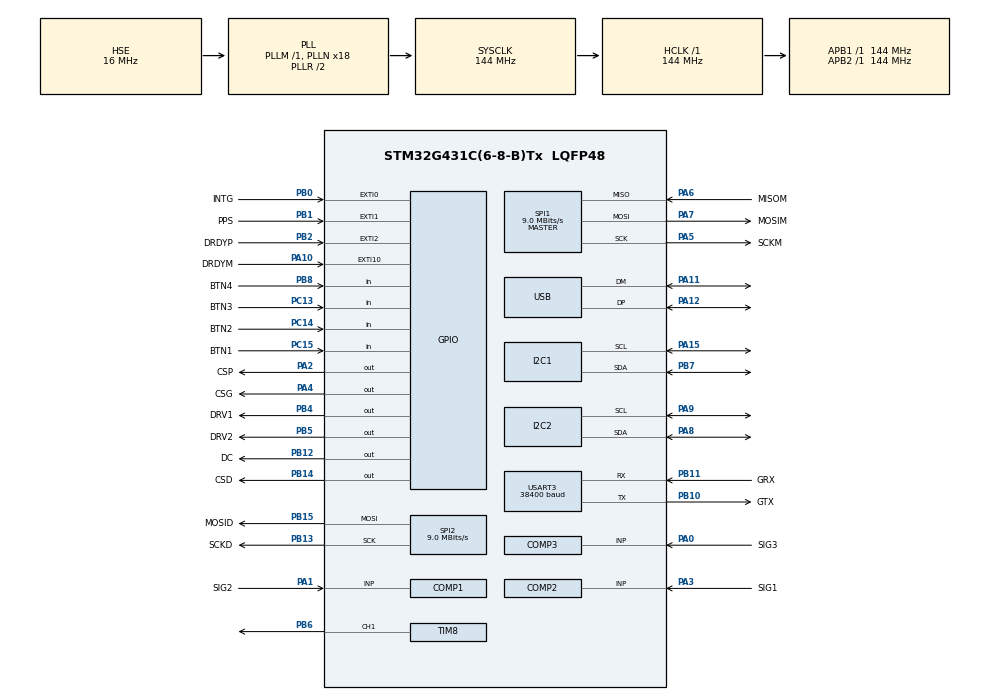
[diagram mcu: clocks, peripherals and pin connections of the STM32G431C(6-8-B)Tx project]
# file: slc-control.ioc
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COMP1.Hysteresis=COMP_HYSTERESIS_HIGH
COMP1.TriggerMode=COMP_TRIGGERMODE_IT_RISING
COMP2.Hysteresis=COMP_HYSTERESIS_HIGH
COMP2.TriggerMode=COMP_TRIGGERMODE_IT_RISING
COMP3.Hysteresis=COMP_HYSTERESIS_HIGH
COMP3.TriggerMode=COMP_TRIGGERMODE_IT_RISING
DAC1.DAC_Channel-DAC_OUT2_Int=DAC_CHANNEL_2
Dma.Request0=USART3_RX
Dma.Request1=USART3_TX
Dma.USART3_RX.0.Direction=DMA_PERIPH_TO_MEMORY
Dma.USART3_RX.0.EventEnable=DISABLE
Dma.USART3_RX.0.Instance=DMA1_Channel1
Dma.USART3_RX.0.MemDataAlignment=DMA_MDATAALIGN_BYTE
Dma.USART3_RX.0.MemInc=DMA_MINC_ENABLE
Dma.USART3_RX.0.Mode=DMA_NORMAL
Dma.USART3_RX.0.PeriphDataAlignment=DMA_PDATAALIGN_BYTE
Dma.USART3_RX.0.PeriphInc=DMA_PINC_DISABLE
Dma.USART3_RX.0.Polarity=HAL_DMAMUX_REQ_GEN_RISING
Dma.USART3_RX.0.Priority=DMA_PRIORITY_HIGH
Dma.USART3_RX.0.RequestNumber=1
Dma.USART3_RX.0.SignalID=NONE
Dma.USART3_RX.0.SyncEnable=DISABLE
Dma.USART3_RX.0.SyncPolarity=HAL_DMAMUX_SYNC_NO_EVENT
Dma.USART3_RX.0.SyncRequestNumber=1
Dma.USART3_RX.0.SyncSignalID=NONE
Dma.USART3_TX.1.Direction=DMA_MEMORY_TO_PERIPH
Dma.USART3_TX.1.EventEnable=DISABLE
Dma.USART3_TX.1.Instance=DMA2_Channel1
Dma.USART3_TX.1.MemDataAlignment=DMA_MDATAALIGN_BYTE
Dma.USART3_TX.1.MemInc=DMA_MINC_ENABLE
Dma.USART3_TX.1.Mode=DMA_NORMAL
Dma.USART3_TX.1.PeriphDataAlignment=DMA_PDATAALIGN_BYTE
Dma.USART3_TX.1.PeriphInc=DMA_PINC_DISABLE
Dma.USART3_TX.1.Polarity=HAL_DMAMUX_REQ_GEN_RISING
Dma.USART3_TX.1.Priority=DMA_PRIORITY_LOW
Dma.USART3_TX.1.RequestNumber=1
Dma.USART3_TX.1.SignalID=NONE
Dma.USART3_TX.1.SyncEnable=DISABLE
Dma.USART3_TX.1.SyncPolarity=HAL_DMAMUX_SYNC_NO_EVENT
Dma.USART3_TX.1.SyncRequestNumber=1
Dma.USART3_TX.1.SyncSignalID=NONE
I2C1.I2C_Fall_Time=10
I2C1.I2C_Rise_Time=10
I2C1.Timing=0xA030354A
I2C2.I2C_Fall_Time=10
I2C2.I2C_Rise_Time=10
I2C2.Timing=0xA030354A
Mcu.Family=STM32G4
Mcu.Name=STM32G431C(6-8-B)Tx
Mcu.Package=LQFP48
NVIC.COMP1_2_3_IRQn=true\:3\:0\:true\:false\:true\:false\:true\:true
NVIC.DMA1_Channel1_IRQn=true\:0\:0\:true\:false\:true\:false\:true\:true
NVIC.PriorityGroup=NVIC_PRIORITYGROUP_4
NVIC.TIM1_UP_TIM16_IRQn=true\:2\:0\:true\:false\:true\:true\:true\:true
NVIC.TIM2_IRQn=true\:4\:0\:true\:false\:true\:true\:true\:true
NVIC.TIM3_IRQn=true\:7\:0\:true\:false\:true\:true\:true\:true
NVIC.USART3_IRQn=true\:1\:0\:true\:false\:true\:true\:true\:true
NVIC.USB_LP_IRQn=true\:0\:0\:true\:false\:true\:false\:true\:true
PA0.GPIO_Label=SIG3
PA0.Mode=INP
PA0.Signal=COMP3_INP
PA1.GPIO_Label=SIG2
PA1.Mode=INP
PA1.Signal=COMP1_INP
PA10.GPIO_Label=DRDYM
PA10.Signal=GPXTI10
PA11.Mode=Device
PA11.Signal=USB_DM
PA12.Mode=Device
PA12.Signal=USB_DP
PA13.Mode=Trace_Asynchronous_SW
PA13.Signal=SYS_JTMS-SWDIO
PA14.Mode=Trace_Asynchronous_SW
PA14.Signal=SYS_JTCK-SWCLK
PA15.Mode=I2C
PA15.Signal=I2C1_SCL
PA2.GPIO_Label=CSP
PA2.GPIO_Speed=GPIO_SPEED_FREQ_HIGH
PA2.PinState=GPIO_PIN_SET
PA2.Signal=GPIO_Output
PA3.GPIO_Label=SIG1
PA3.Mode=INP
PA3.Signal=COMP2_INP
PA4.GPIO_Label=CSG
PA4.GPIO_Speed=GPIO_SPEED_FREQ_HIGH
PA4.PinState=GPIO_PIN_SET
PA4.Signal=GPIO_Output
PA5.GPIO_Label=SCKM
PA5.Mode=Full_Duplex_Master
PA5.Signal=SPI1_SCK
PA6.GPIO_Label=MISOM
PA6.Mode=Full_Duplex_Master
PA6.Signal=SPI1_MISO
PA7.GPIO_Label=MOSIM
PA7.Mode=Full_Duplex_Master
PA7.Signal=SPI1_MOSI
PA8.Mode=I2C
PA8.Signal=I2C2_SDA
PA9.Mode=I2C
PA9.Signal=I2C2_SCL
PB0.GPIO_Label=INTG
PB0.Signal=GPXTI0
PB1.GPIO_Label=PPS
PB1.Signal=GPXTI1
PB10.GPIO_Label=GTX
PB10.Mode=Asynchronous
PB10.Signal=USART3_TX
PB11.GPIO_Label=GRX
PB11.Mode=Asynchronous
PB11.Signal=USART3_RX
PB12.GPIO_Label=DC
PB12.GPIO_Speed=GPIO_SPEED_FREQ_HIGH
PB12.Signal=GPIO_Output
PB13.GPIO_Label=SCKD
PB13.Mode=TX_Only_Simplex_Unidirect_Master
PB13.Signal=SPI2_SCK
PB14.GPIO_Label=CSD
PB14.GPIO_Speed=GPIO_SPEED_FREQ_HIGH
PB14.PinState=GPIO_PIN_SET
PB14.Signal=GPIO_Output
PB15.GPIO_Label=MOSID
PB15.Mode=TX_Only_Simplex_Unidirect_Master
PB15.Signal=SPI2_MOSI
PB2.GPIO_Label=DRDYP
PB2.Signal=GPXTI2
PB3.Mode=Trace_Asynchronous_SW
PB3.Signal=SYS_JTDO-SWO
PB4.GPIO_Label=DRV1
PB4.GPIO_Speed=GPIO_SPEED_FREQ_MEDIUM
PB4.Signal=GPIO_Output
PB5.GPIO_Label=DRV2
PB5.GPIO_Speed=GPIO_SPEED_FREQ_MEDIUM
PB5.Signal=GPIO_Output
PB6.Signal=S_TIM8_CH1
PB7.Mode=I2C
PB7.Signal=I2C1_SDA
PB8-BOOT0.GPIO_Label=BTN4
PB8-BOOT0.GPIO_PuPd=GPIO_PULLUP
PB8-BOOT0.Signal=GPIO_Input
PC13.GPIO_Label=BTN3
PC13.GPIO_PuPd=GPIO_PULLUP
PC13.Signal=GPIO_Input
PC14-OSC32_IN.GPIO_Label=BTN2
PC14-OSC32_IN.GPIO_PuPd=GPIO_PULLUP
PC14-OSC32_IN.Signal=GPIO_Input
PC15-OSC32_OUT.GPIO_Label=BTN1
PC15-OSC32_OUT.GPIO_PuPd=GPIO_PULLUP
PC15-OSC32_OUT.Signal=GPIO_Input
PF0-OSC_IN.Mode=HSE-External-Oscillator
PF0-OSC_IN.Signal=RCC_OSC_IN
PF1-OSC_OUT.Mode=HSE-External-Oscillator
PF1-OSC_OUT.Signal=RCC_OSC_OUT
ProjectManager.HeapSize=0x200
ProjectManager.StackSize=0x400
ProjectManager.TargetToolchain=CMake
RCC.ADC12Freq_Value=144000000
RCC.AHBFreq_Value=144000000
RCC.APB1Freq_Value=144000000
RCC.APB1TimFreq_Value=144000000
RCC.APB2Freq_Value=144000000
RCC.APB2TimFreq_Value=144000000
RCC.CortexFreq_Value=144000000
RCC.EXTERNAL_CLOCK_VALUE=12288000
RCC.HCLKFreq_Value=144000000
RCC.HSE_Timout=1000
RCC.HSE_VALUE=16000000
RCC.HSI48_VALUE=48000000
RCC.HSI_VALUE=16000000
RCC.I2C1CLockSelection=RCC_I2C1CLKSOURCE_SYSCLK
RCC.I2C2CLockSelection=RCC_I2C2CLKSOURCE_SYSCLK
RCC.LSE_VALUE=32768
RCC.PLLN=18
RCC.PLLQ=RCC_PLLQ_DIV6
RCC.PLLSourceVirtual=RCC_PLLSOURCE_HSE
RCC.PREFETCH_ENABLE=1
RCC.SYSCLKFreq_VALUE=144000000
RCC.SYSCLKSource=RCC_SYSCLKSOURCE_PLLCLK
RCC.USART3CLockSelection=RCC_USART3CLKSOURCE_SYSCLK
RCC.USBFreq_Value=48000000
RCC.VCOOutputFreq_Value=288000000
SH.S_TIM8_CH1.0=TIM8_CH1,PWM Generation1 CH1
SPI1.BaudRatePrescaler=SPI_BAUDRATEPRESCALER_16
SPI1.CalculateBaudRate=9.0 MBits/s
SPI1.DataSize=SPI_DATASIZE_8BIT
SPI1.Direction=SPI_DIRECTION_2LINES
SPI1.Mode=SPI_MODE_MASTER
SPI1.VirtualType=VM_MASTER
SPI2.BaudRatePrescaler=SPI_BAUDRATEPRESCALER_16
SPI2.CalculateBaudRate=9.0 MBits/s
SPI2.DataSize=SPI_DATASIZE_8BIT
SPI2.Direction=SPI_DIRECTION_2LINES
SPI2.Mode=SPI_MODE_MASTER
SPI2.VirtualType=VM_MASTER
TIM1.PeriodNoDither=100-1
TIM1.Prescaler=144-1
TIM2.PeriodNoDither=100000-1
TIM2.Prescaler=144-1
TIM3.PeriodNoDither=20000-1
TIM3.Prescaler=144-1
TIM8.Channel-PWM\ Generation1\ CH1=TIM_CHANNEL_1
TIM8.PeriodNoDither=1000
TIM8.Prescaler=65535
TIM8.PulseNoDither_1=100
USART3.BaudRate=38400
USART3.VirtualMode-Asynchronous=VM_ASYNC
USB_DEVICE.CLASS_NAME_FS=CDC
USB_DEVICE.PRODUCT_STRING_CDC_FS=slc-control
USB_DEVICE.VirtualMode=Cdc
USB_DEVICE.VirtualModeFS=Cdc_FS
VP_COMP1_VS_DAC1OUT1.Mode=INM_DAC1OUT1
VP_COMP2_VS_DAC1OUT2.Mode=INM_DAC1OUT2
VP_COMP3_VS_DAC3OUT1.Mode=INM_DAC3OUT1
VP_DAC1_VS_DACI1.Mode=DAC_OUT1_Int
VP_DAC1_VS_DACI2.Mode=DAC_OUT2_Int
VP_DAC3_VS_DACI1.Mode=DAC_OUT1_Int
VP_SYS_VS_DBSignals.Mode=DisableDeadBatterySignals
VP_TIM1_VS_ClockSourceINT.Mode=Internal
VP_TIM2_VS_ClockSourceINT.Mode=Internal
VP_TIM3_VS_ClockSourceINT.Mode=Internal
VP_TIM8_VS_ClockSourceINT.Mode=Internal
VP_USB_DEVICE_VS_USB_DEVICE_CDC_FS.Mode=CDC_FS
board=custom

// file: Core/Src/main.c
/* USER CODE BEGIN Header */
/**
  ******************************************************************************
  * @file           : main.c
  * @brief          : Main program body
  ******************************************************************************
  * @attention
  *
  * Copyright (c) 2025 STMicroelectronics.
  * All rights reserved.
  *
  * This software is licensed under terms that can be found in the LICENSE file
  * in the root directory of this software component.
  * If no LICENSE file comes with this software, it is provided AS-IS.
  *
  ******************************************************************************
  */
/* USER CODE END Header */
#include "main.h"
#include "usb_device.h"

/* USER CODE BEGIN Includes */
#include "app.h"
/* USER CODE END Includes */

COMP_HandleTypeDef hcomp1;
COMP_HandleTypeDef hcomp2;
COMP_HandleTypeDef hcomp3;

DAC_HandleTypeDef hdac1;
DAC_HandleTypeDef hdac3;

I2C_HandleTypeDef hi2c1;
I2C_HandleTypeDef hi2c2;

SPI_HandleTypeDef hspi1;
SPI_HandleTypeDef hspi2;

TIM_HandleTypeDef htim1;
TIM_HandleTypeDef htim2;
TIM_HandleTypeDef htim3;
TIM_HandleTypeDef htim8;

UART_HandleTypeDef huart3;
DMA_HandleTypeDef hdma_usart3_rx;
DMA_HandleTypeDef hdma_usart3_tx;

void SystemClock_Config(void);
static void MX_GPIO_Init(void);
static void MX_DMA_Init(void);
static void MX_I2C1_Init(void);
static void MX_I2C2_Init(void);
static void MX_SPI1_Init(void);
static void MX_SPI2_Init(void);
static void MX_USART3_UART_Init(void);
static void MX_COMP1_Init(void);
static void MX_COMP2_Init(void);
static void MX_COMP3_Init(void);
static void MX_DAC1_Init(void);
static void MX_DAC3_Init(void);
static void MX_TIM1_Init(void);
static void MX_TIM2_Init(void);
static void MX_TIM3_Init(void);
static void MX_TIM8_Init(void);

int main(void)
{

  /* MCU Configuration--------------------------------------------------------*/

  /* Reset of all peripherals, Initializes the Flash interface and the Systick. */
  HAL_Init();

  /* Configure the system clock */
  SystemClock_Config();

  /* Initialize all configured peripherals */
  MX_GPIO_Init();
  MX_DMA_Init();
  MX_I2C1_Init();
  MX_I2C2_Init();
  MX_SPI1_Init();
  MX_SPI2_Init();
  MX_USART3_UART_Init();
  MX_USB_Device_Init();
  MX_COMP1_Init();
  MX_COMP2_Init();
  MX_COMP3_Init();
  MX_DAC1_Init();
  MX_DAC3_Init();
  MX_TIM1_Init();
  MX_TIM2_Init();
  MX_TIM3_Init();
  MX_TIM8_Init();

  /* Infinite loop */
  /* USER CODE BEGIN WHILE */
  App_Init();
  while (1)
  {
    App_Update();
    /* USER CODE END WHILE */

  }
}

void SystemClock_Config(void)
{
  RCC_OscInitTypeDef RCC_OscInitStruct = {0};
  RCC_ClkInitTypeDef RCC_ClkInitStruct = {0};

  /** Configure the main internal regulator output voltage
  */
  HAL_PWREx_ControlVoltageScaling(PWR_REGULATOR_VOLTAGE_SCALE1);

  /** Initializes the RCC Oscillators according to the specified parameters
  * in the RCC_OscInitTypeDef structure.
  */
  RCC_OscInitStruct.OscillatorType = RCC_OSCILLATORTYPE_HSE;
  RCC_OscInitStruct.HSEState = RCC_HSE_ON;
  RCC_OscInitStruct.PLL.PLLState = RCC_PLL_ON;
  RCC_OscInitStruct.PLL.PLLSource = RCC_PLLSOURCE_HSE;
  RCC_OscInitStruct.PLL.PLLM = RCC_PLLM_DIV1;
  RCC_OscInitStruct.PLL.PLLN = 18;
  RCC_OscInitStruct.PLL.PLLP = RCC_PLLP_DIV2;
  RCC_OscInitStruct.PLL.PLLQ = RCC_PLLQ_DIV6;
  RCC_OscInitStruct.PLL.PLLR = RCC_PLLR_DIV2;
  if (HAL_RCC_OscConfig(&RCC_OscInitStruct) != HAL_OK)
  {
    Error_Handler();
  }

  /** Initializes the CPU, AHB and APB buses clocks
  */
  RCC_ClkInitStruct.ClockType = RCC_CLOCKTYPE_HCLK|RCC_CLOCKTYPE_SYSCLK
                              |RCC_CLOCKTYPE_PCLK1|RCC_CLOCKTYPE_PCLK2;
  RCC_ClkInitStruct.SYSCLKSource = RCC_SYSCLKSOURCE_PLLCLK;
  RCC_ClkInitStruct.AHBCLKDivider = RCC_SYSCLK_DIV1;
  RCC_ClkInitStruct.APB1CLKDivider = RCC_HCLK_DIV1;
  RCC_ClkInitStruct.APB2CLKDivider = RCC_HCLK_DIV1;

  if (HAL_RCC_ClockConfig(&RCC_ClkInitStruct, FLASH_LATENCY_4) != HAL_OK)
  {
    Error_Handler();
  }
}

static void MX_COMP1_Init(void)
{

  hcomp1.Instance = COMP1;
  hcomp1.Init.InputPlus = COMP_INPUT_PLUS_IO1;
  hcomp1.Init.InputMinus = COMP_INPUT_MINUS_DAC1_CH1;
  hcomp1.Init.OutputPol = COMP_OUTPUTPOL_NONINVERTED;
  hcomp1.Init.Hysteresis = COMP_HYSTERESIS_HIGH;
  hcomp1.Init.BlankingSrce = COMP_BLANKINGSRC_NONE;
  hcomp1.Init.TriggerMode = COMP_TRIGGERMODE_IT_RISING;
  if (HAL_COMP_Init(&hcomp1) != HAL_OK)
  {
    Error_Handler();
  }

}

static void MX_COMP2_Init(void)
{

  hcomp2.Instance = COMP2;
  hcomp2.Init.InputPlus = COMP_INPUT_PLUS_IO2;
  hcomp2.Init.InputMinus = COMP_INPUT_MINUS_DAC1_CH2;
  hcomp2.Init.OutputPol = COMP_OUTPUTPOL_NONINVERTED;
  hcomp2.Init.Hysteresis = COMP_HYSTERESIS_HIGH;
  hcomp2.Init.BlankingSrce = COMP_BLANKINGSRC_NONE;
  hcomp2.Init.TriggerMode = COMP_TRIGGERMODE_IT_RISING;
  if (HAL_COMP_Init(&hcomp2) != HAL_OK)
  {
    Error_Handler();
  }

}

static void MX_COMP3_Init(void)
{

  hcomp3.Instance = COMP3;
  hcomp3.Init.InputPlus = COMP_INPUT_PLUS_IO1;
  hcomp3.Init.InputMinus = COMP_INPUT_MINUS_DAC3_CH1;
  hcomp3.Init.OutputPol = COMP_OUTPUTPOL_NONINVERTED;
  hcomp3.Init.Hysteresis = COMP_HYSTERESIS_HIGH;
  hcomp3.Init.BlankingSrce = COMP_BLANKINGSRC_NONE;
  hcomp3.Init.TriggerMode = COMP_TRIGGERMODE_IT_RISING;
  if (HAL_COMP_Init(&hcomp3) != HAL_OK)
  {
    Error_Handler();
  }

}

static void MX_DAC1_Init(void)
{

  DAC_ChannelConfTypeDef sConfig = {0};

  /** DAC Initialization
  */
  hdac1.Instance = DAC1;
  if (HAL_DAC_Init(&hdac1) != HAL_OK)
  {
    Error_Handler();
  }

  /** DAC channel OUT1 config
  */
  sConfig.DAC_HighFrequency = DAC_HIGH_FREQUENCY_INTERFACE_MODE_AUTOMATIC;
  sConfig.DAC_DMADoubleDataMode = DISABLE;
  sConfig.DAC_SignedFormat = DISABLE;
  sConfig.DAC_SampleAndHold = DAC_SAMPLEANDHOLD_DISABLE;
  sConfig.DAC_Trigger = DAC_TRIGGER_NONE;
  sConfig.DAC_Trigger2 = DAC_TRIGGER_NONE;
  sConfig.DAC_OutputBuffer = DAC_OUTPUTBUFFER_DISABLE;
  sConfig.DAC_ConnectOnChipPeripheral = DAC_CHIPCONNECT_INTERNAL;
  sConfig.DAC_UserTrimming = DAC_TRIMMING_FACTORY;
  if (HAL_DAC_ConfigChannel(&hdac1, &sConfig, DAC_CHANNEL_1) != HAL_OK)
  {
    Error_Handler();
  }

  /** DAC channel OUT2 config
  */
  if (HAL_DAC_ConfigChannel(&hdac1, &sConfig, DAC_CHANNEL_2) != HAL_OK)
  {
    Error_Handler();
  }

}

static void MX_DAC3_Init(void)
{

  DAC_ChannelConfTypeDef sConfig = {0};

  /** DAC Initialization
  */
  hdac3.Instance = DAC3;
  if (HAL_DAC_Init(&hdac3) != HAL_OK)
  {
    Error_Handler();
  }

  /** DAC channel OUT1 config
  */
  sConfig.DAC_HighFrequency = DAC_HIGH_FREQUENCY_INTERFACE_MODE_AUTOMATIC;
  sConfig.DAC_DMADoubleDataMode = DISABLE;
  sConfig.DAC_SignedFormat = DISABLE;
  sConfig.DAC_SampleAndHold = DAC_SAMPLEANDHOLD_DISABLE;
  sConfig.DAC_Trigger = DAC_TRIGGER_NONE;
  sConfig.DAC_Trigger2 = DAC_TRIGGER_NONE;
  sConfig.DAC_OutputBuffer = DAC_OUTPUTBUFFER_DISABLE;
  sConfig.DAC_ConnectOnChipPeripheral = DAC_CHIPCONNECT_INTERNAL;
  sConfig.DAC_UserTrimming = DAC_TRIMMING_FACTORY;
  if (HAL_DAC_ConfigChannel(&hdac3, &sConfig, DAC_CHANNEL_1) != HAL_OK)
  {
    Error_Handler();
  }

}

static void MX_I2C1_Init(void)
{

  hi2c1.Instance = I2C1;
  hi2c1.Init.Timing = 0xA030354A;
  hi2c1.Init.OwnAddress1 = 0;
  hi2c1.Init.AddressingMode = I2C_ADDRESSINGMODE_7BIT;
  hi2c1.Init.DualAddressMode = I2C_DUALADDRESS_DISABLE;
  hi2c1.Init.OwnAddress2 = 0;
  hi2c1.Init.OwnAddress2Masks = I2C_OA2_NOMASK;
  hi2c1.Init.GeneralCallMode = I2C_GENERALCALL_DISABLE;
  hi2c1.Init.NoStretchMode = I2C_NOSTRETCH_DISABLE;
  if (HAL_I2C_Init(&hi2c1) != HAL_OK)
  {
    Error_Handler();
  }

  /** Configure Analogue filter
  */
  if (HAL_I2CEx_ConfigAnalogFilter(&hi2c1, I2C_ANALOGFILTER_ENABLE) != HAL_OK)
  {
    Error_Handler();
  }

  /** Configure Digital filter
  */
  if (HAL_I2CEx_ConfigDigitalFilter(&hi2c1, 0) != HAL_OK)
  {
    Error_Handler();
  }

}

static void MX_I2C2_Init(void)
{

  hi2c2.Instance = I2C2;
  hi2c2.Init.Timing = 0xA030354A;
  hi2c2.Init.OwnAddress1 = 0;
  hi2c2.Init.AddressingMode = I2C_ADDRESSINGMODE_7BIT;
  hi2c2.Init.DualAddressMode = I2C_DUALADDRESS_DISABLE;
  hi2c2.Init.OwnAddress2 = 0;
  hi2c2.Init.OwnAddress2Masks = I2C_OA2_NOMASK;
  hi2c2.Init.GeneralCallMode = I2C_GENERALCALL_DISABLE;
  hi2c2.Init.NoStretchMode = I2C_NOSTRETCH_DISABLE;
  if (HAL_I2C_Init(&hi2c2) != HAL_OK)
  {
    Error_Handler();
  }

  /** Configure Analogue filter
  */
  if (HAL_I2CEx_ConfigAnalogFilter(&hi2c2, I2C_ANALOGFILTER_ENABLE) != HAL_OK)
  {
    Error_Handler();
  }

  /** Configure Digital filter
  */
  if (HAL_I2CEx_ConfigDigitalFilter(&hi2c2, 0) != HAL_OK)
  {
    Error_Handler();
  }

}

static void MX_SPI1_Init(void)
{

  /* SPI1 parameter configuration*/
  hspi1.Instance = SPI1;
  hspi1.Init.Mode = SPI_MODE_MASTER;
  hspi1.Init.Direction = SPI_DIRECTION_2LINES;
  hspi1.Init.DataSize = SPI_DATASIZE_8BIT;
  hspi1.Init.CLKPolarity = SPI_POLARITY_LOW;
  hspi1.Init.CLKPhase = SPI_PHASE_1EDGE;
  hspi1.Init.NSS = SPI_NSS_SOFT;
  hspi1.Init.BaudRatePrescaler = SPI_BAUDRATEPRESCALER_16;
  hspi1.Init.FirstBit = SPI_FIRSTBIT_MSB;
  hspi1.Init.TIMode = SPI_TIMODE_DISABLE;
  hspi1.Init.CRCCalculation = SPI_CRCCALCULATION_DISABLE;
  hspi1.Init.CRCPolynomial = 7;
  hspi1.Init.CRCLength = SPI_CRC_LENGTH_DATASIZE;
  hspi1.Init.NSSPMode = SPI_NSS_PULSE_ENABLE;
  if (HAL_SPI_Init(&hspi1) != HAL_OK)
  {
    Error_Handler();
  }

}

static void MX_SPI2_Init(void)
{

  /* SPI2 parameter configuration*/
  hspi2.Instance = SPI2;
  hspi2.Init.Mode = SPI_MODE_MASTER;
  hspi2.Init.Direction = SPI_DIRECTION_2LINES;
  hspi2.Init.DataSize = SPI_DATASIZE_8BIT;
  hspi2.Init.CLKPolarity = SPI_POLARITY_LOW;
  hspi2.Init.CLKPhase = SPI_PHASE_1EDGE;
  hspi2.Init.NSS = SPI_NSS_SOFT;
  hspi2.Init.BaudRatePrescaler = SPI_BAUDRATEPRESCALER_16;
  hspi2.Init.FirstBit = SPI_FIRSTBIT_MSB;
  hspi2.Init.TIMode = SPI_TIMODE_DISABLE;
  hspi2.Init.CRCCalculation = SPI_CRCCALCULATION_DISABLE;
  hspi2.Init.CRCPolynomial = 7;
  hspi2.Init.CRCLength = SPI_CRC_LENGTH_DATASIZE;
  hspi2.Init.NSSPMode = SPI_NSS_PULSE_ENABLE;
  if (HAL_SPI_Init(&hspi2) != HAL_OK)
  {
    Error_Handler();
  }

}

static void MX_TIM1_Init(void)
{

  TIM_ClockConfigTypeDef sClockSourceConfig = {0};
  TIM_MasterConfigTypeDef sMasterConfig = {0};

  htim1.Instance = TIM1;
  htim1.Init.Prescaler = 144-1;
  htim1.Init.CounterMode = TIM_COUNTERMODE_UP;
  htim1.Init.Period = 99;
  htim1.Init.ClockDivision = TIM_CLOCKDIVISION_DIV1;
  htim1.Init.RepetitionCounter = 0;
  htim1.Init.AutoReloadPreload = TIM_AUTORELOAD_PRELOAD_DISABLE;
  if (HAL_TIM_Base_Init(&htim1) != HAL_OK)
  {
    Error_Handler();
  }
  sClockSourceConfig.ClockSource = TIM_CLOCKSOURCE_INTERNAL;
  if (HAL_TIM_ConfigClockSource(&htim1, &sClockSourceConfig) != HAL_OK)
  {
    Error_Handler();
  }
  sMasterConfig.MasterOutputTrigger = TIM_TRGO_RESET;
  sMasterConfig.MasterOutputTrigger2 = TIM_TRGO2_RESET;
  sMasterConfig.MasterSlaveMode = TIM_MASTERSLAVEMODE_DISABLE;
  if (HAL_TIMEx_MasterConfigSynchronization(&htim1, &sMasterConfig) != HAL_OK)
  {
    Error_Handler();
  }

}

static void MX_TIM2_Init(void)
{

  TIM_ClockConfigTypeDef sClockSourceConfig = {0};
  TIM_MasterConfigTypeDef sMasterConfig = {0};

  htim2.Instance = TIM2;
  htim2.Init.Prescaler = 144-1;
  htim2.Init.CounterMode = TIM_COUNTERMODE_UP;
  htim2.Init.Period = 99999;
  htim2.Init.ClockDivision = TIM_CLOCKDIVISION_DIV1;
  htim2.Init.AutoReloadPreload = TIM_AUTORELOAD_PRELOAD_DISABLE;
  if (HAL_TIM_Base_Init(&htim2) != HAL_OK)
  {
    Error_Handler();
  }
  sClockSourceConfig.ClockSource = TIM_CLOCKSOURCE_INTERNAL;
  if (HAL_TIM_ConfigClockSource(&htim2, &sClockSourceConfig) != HAL_OK)
  {
    Error_Handler();
  }
  sMasterConfig.MasterOutputTrigger = TIM_TRGO_RESET;
  sMasterConfig.MasterSlaveMode = TIM_MASTERSLAVEMODE_DISABLE;
  if (HAL_TIMEx_MasterConfigSynchronization(&htim2, &sMasterConfig) != HAL_OK)
  {
    Error_Handler();
  }

}

static void MX_TIM3_Init(void)
{

  TIM_ClockConfigTypeDef sClockSourceConfig = {0};
  TIM_MasterConfigTypeDef sMasterConfig = {0};

  htim3.Instance = TIM3;
  htim3.Init.Prescaler = 144-1;
  htim3.Init.CounterMode = TIM_COUNTERMODE_UP;
  htim3.Init.Period = 19999;
  htim3.Init.ClockDivision = TIM_CLOCKDIVISION_DIV1;
  htim3.Init.AutoReloadPreload = TIM_AUTORELOAD_PRELOAD_DISABLE;
  if (HAL_TIM_Base_Init(&htim3) != HAL_OK)
  {
    Error_Handler();
  }
  sClockSourceConfig.ClockSource = TIM_CLOCKSOURCE_INTERNAL;
  if (HAL_TIM_ConfigClockSource(&htim3, &sClockSourceConfig) != HAL_OK)
  {
    Error_Handler();
  }
  sMasterConfig.MasterOutputTrigger = TIM_TRGO_RESET;
  sMasterConfig.MasterSlaveMode = TIM_MASTERSLAVEMODE_DISABLE;
  if (HAL_TIMEx_MasterConfigSynchronization(&htim3, &sMasterConfig) != HAL_OK)
  {
    Error_Handler();
  }

}

static void MX_TIM8_Init(void)
{

  TIM_ClockConfigTypeDef sClockSourceConfig = {0};
  TIM_MasterConfigTypeDef sMasterConfig = {0};
  TIM_OC_InitTypeDef sConfigOC = {0};
  TIM_BreakDeadTimeConfigTypeDef sBreakDeadTimeConfig = {0};

  htim8.Instance = TIM8;
  htim8.Init.Prescaler = 65535;
  htim8.Init.CounterMode = TIM_COUNTERMODE_UP;
  htim8.Init.Period = 1000;
  htim8.Init.ClockDivision = TIM_CLOCKDIVISION_DIV1;
  htim8.Init.RepetitionCounter = 0;
  htim8.Init.AutoReloadPreload = TIM_AUTORELOAD_PRELOAD_DISABLE;
  if (HAL_TIM_Base_Init(&htim8) != HAL_OK)
  {
    Error_Handler();
  }
  sClockSourceConfig.ClockSource = TIM_CLOCKSOURCE_INTERNAL;
  if (HAL_TIM_ConfigClockSource(&htim8, &sClockSourceConfig) != HAL_OK)
  {
    Error_Handler();
  }
  if (HAL_TIM_PWM_Init(&htim8) != HAL_OK)
  {
    Error_Handler();
  }
  sMasterConfig.MasterOutputTrigger = TIM_TRGO_RESET;
  sMasterConfig.MasterOutputTrigger2 = TIM_TRGO2_RESET;
  sMasterConfig.MasterSlaveMode = TIM_MASTERSLAVEMODE_DISABLE;
  if (HAL_TIMEx_MasterConfigSynchronization(&htim8, &sMasterConfig) != HAL_OK)
  {
    Error_Handler();
  }
  sConfigOC.OCMode = TIM_OCMODE_PWM1;
  sConfigOC.Pulse = 100;
  sConfigOC.OCPolarity = TIM_OCPOLARITY_HIGH;
  sConfigOC.OCNPolarity = TIM_OCNPOLARITY_HIGH;
  sConfigOC.OCFastMode = TIM_OCFAST_DISABLE;
  sConfigOC.OCIdleState = TIM_OCIDLESTATE_RESET;
  sConfigOC.OCNIdleState = TIM_OCNIDLESTATE_RESET;
  if (HAL_TIM_PWM_ConfigChannel(&htim8, &sConfigOC, TIM_CHANNEL_1) != HAL_OK)
  {
    Error_Handler();
  }
  sBreakDeadTimeConfig.OffStateRunMode = TIM_OSSR_DISABLE;
  sBreakDeadTimeConfig.OffStateIDLEMode = TIM_OSSI_DISABLE;
  sBreakDeadTimeConfig.LockLevel = TIM_LOCKLEVEL_OFF;
  sBreakDeadTimeConfig.DeadTime = 0;
  sBreakDeadTimeConfig.BreakState = TIM_BREAK_DISABLE;
  sBreakDeadTimeConfig.BreakPolarity = TIM_BREAKPOLARITY_HIGH;
  sBreakDeadTimeConfig.BreakFilter = 0;
  sBreakDeadTimeConfig.BreakAFMode = TIM_BREAK_AFMODE_INPUT;
  sBreakDeadTimeConfig.Break2State = TIM_BREAK2_DISABLE;
  sBreakDeadTimeConfig.Break2Polarity = TIM_BREAK2POLARITY_HIGH;
  sBreakDeadTimeConfig.Break2Filter = 0;
  sBreakDeadTimeConfig.Break2AFMode = TIM_BREAK_AFMODE_INPUT;
  sBreakDeadTimeConfig.AutomaticOutput = TIM_AUTOMATICOUTPUT_DISABLE;
  if (HAL_TIMEx_ConfigBreakDeadTime(&htim8, &sBreakDeadTimeConfig) != HAL_OK)
  {
    Error_Handler();
  }
  HAL_TIM_MspPostInit(&htim8);

}

static void MX_USART3_UART_Init(void)
{

  huart3.Instance = USART3;
  huart3.Init.BaudRate = 38400;
  huart3.Init.WordLength = UART_WORDLENGTH_8B;
  huart3.Init.StopBits = UART_STOPBITS_1;
  huart3.Init.Parity = UART_PARITY_NONE;
  huart3.Init.Mode = UART_MODE_TX_RX;
  huart3.Init.HwFlowCtl = UART_HWCONTROL_NONE;
  huart3.Init.OverSampling = UART_OVERSAMPLING_16;
  huart3.Init.OneBitSampling = UART_ONE_BIT_SAMPLE_DISABLE;
  huart3.Init.ClockPrescaler = UART_PRESCALER_DIV1;
  huart3.AdvancedInit.AdvFeatureInit = UART_ADVFEATURE_NO_INIT;
  if (HAL_UART_Init(&huart3) != HAL_OK)
  {
    Error_Handler();
  }
  if (HAL_UARTEx_SetTxFifoThreshold(&huart3, UART_TXFIFO_THRESHOLD_1_8) != HAL_OK)
  {
    Error_Handler();
  }
  if (HAL_UARTEx_SetRxFifoThreshold(&huart3, UART_RXFIFO_THRESHOLD_1_8) != HAL_OK)
  {
    Error_Handler();
  }
  if (HAL_UARTEx_DisableFifoMode(&huart3) != HAL_OK)
  {
    Error_Handler();
  }

}

static void MX_DMA_Init(void)
{

  /* DMA controller clock enable */
  __HAL_RCC_DMAMUX1_CLK_ENABLE();
  __HAL_RCC_DMA1_CLK_ENABLE();
  __HAL_RCC_DMA2_CLK_ENABLE();

  /* DMA interrupt init */
  /* DMA1_Channel1_IRQn interrupt configuration */
  HAL_NVIC_SetPriority(DMA1_Channel1_IRQn, 0, 0);
  HAL_NVIC_EnableIRQ(DMA1_Channel1_IRQn);

}

static void MX_GPIO_Init(void)
{
  GPIO_InitTypeDef GPIO_InitStruct = {0};

  /* GPIO Ports Clock Enable */
  __HAL_RCC_GPIOC_CLK_ENABLE();
  __HAL_RCC_GPIOF_CLK_ENABLE();
  __HAL_RCC_GPIOA_CLK_ENABLE();
  __HAL_RCC_GPIOB_CLK_ENABLE();

  /*Configure GPIO pin Output Level */
  HAL_GPIO_WritePin(GPIOA, CSP_Pin|CSG_Pin, GPIO_PIN_SET);

  /*Configure GPIO pin Output Level */
  HAL_GPIO_WritePin(GPIOB, DC_Pin|DRV1_Pin|DRV2_Pin, GPIO_PIN_RESET);

  /*Configure GPIO pin Output Level */
  HAL_GPIO_WritePin(CSD_GPIO_Port, CSD_Pin, GPIO_PIN_SET);

  /*Configure GPIO pins : BTN3_Pin BTN2_Pin BTN1_Pin */
  GPIO_InitStruct.Pin = BTN3_Pin|BTN2_Pin|BTN1_Pin;
  GPIO_InitStruct.Mode = GPIO_MODE_INPUT;
  GPIO_InitStruct.Pull = GPIO_PULLUP;
  HAL_GPIO_Init(GPIOC, &GPIO_InitStruct);

  /*Configure GPIO pins : CSP_Pin CSG_Pin */
  GPIO_InitStruct.Pin = CSP_Pin|CSG_Pin;
  GPIO_InitStruct.Mode = GPIO_MODE_OUTPUT_PP;
  GPIO_InitStruct.Pull = GPIO_NOPULL;
  GPIO_InitStruct.Speed = GPIO_SPEED_FREQ_HIGH;
  HAL_GPIO_Init(GPIOA, &GPIO_InitStruct);

  /*Configure GPIO pins : INTG_Pin PPS_Pin DRDYP_Pin */
  GPIO_InitStruct.Pin = INTG_Pin|PPS_Pin|DRDYP_Pin;
  GPIO_InitStruct.Mode = GPIO_MODE_IT_RISING;
  GPIO_InitStruct.Pull = GPIO_NOPULL;
  HAL_GPIO_Init(GPIOB, &GPIO_InitStruct);

  /*Configure GPIO pins : DC_Pin CSD_Pin */
  GPIO_InitStruct.Pin = DC_Pin|CSD_Pin;
  GPIO_InitStruct.Mode = GPIO_MODE_OUTPUT_PP;
  GPIO_InitStruct.Pull = GPIO_NOPULL;
  GPIO_InitStruct.Speed = GPIO_SPEED_FREQ_HIGH;
  HAL_GPIO_Init(GPIOB, &GPIO_InitStruct);

  /*Configure GPIO pin : DRDYM_Pin */
  GPIO_InitStruct.Pin = DRDYM_Pin;
  GPIO_InitStruct.Mode = GPIO_MODE_IT_RISING;
  GPIO_InitStruct.Pull = GPIO_NOPULL;
  HAL_GPIO_Init(DRDYM_GPIO_Port, &GPIO_InitStruct);

  /*Configure GPIO pins : DRV1_Pin DRV2_Pin */
  GPIO_InitStruct.Pin = DRV1_Pin|DRV2_Pin;
  GPIO_InitStruct.Mode = GPIO_MODE_OUTPUT_PP;
  GPIO_InitStruct.Pull = GPIO_NOPULL;
  GPIO_InitStruct.Speed = GPIO_SPEED_FREQ_MEDIUM;
  HAL_GPIO_Init(GPIOB, &GPIO_InitStruct);

  /*Configure GPIO pin : BTN4_Pin */
  GPIO_InitStruct.Pin = BTN4_Pin;
  GPIO_InitStruct.Mode = GPIO_MODE_INPUT;
  GPIO_InitStruct.Pull = GPIO_PULLUP;
  HAL_GPIO_Init(BTN4_GPIO_Port, &GPIO_InitStruct);

}

void Error_Handler(void)
{
  __disable_irq();
  while (1)
  {
  }
}

#ifdef  USE_FULL_ASSERT
/**
  * @brief  Reports the name of the source file and the source line number
  *         where the assert_param error has occurred.
  * @param  file: pointer to the source file name
  * @param  line: assert_param error line source number
  * @retval None
  */
void assert_failed(uint8_t *file, uint32_t line)
{
  /* USER CODE BEGIN 6 */
  // User can add his own implementation to report the file name and line number,
  //    printf("Wrong parameters value: file %s on line %d\r\n", file, line)
  /* USER CODE END 6 */
}
#endif /* USE_FULL_ASSERT */
